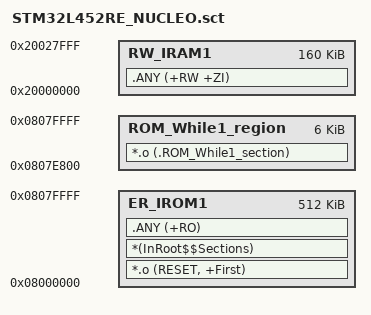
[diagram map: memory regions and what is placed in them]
; *************************************************************
; *** Scatter-Loading Description File generated by uVision ***
; *************************************************************

LR_IROM1 0x08000000 0x00080000  {    ; load region size_region
  ER_IROM1 0x08000000 0x00080000  {  ; load address = execution address
   *.o (RESET, +First)
   *(InRoot$$Sections)
   .ANY (+RO)
  }
  ROM_While1_region 0x0807E800 0x1800  {
   *.o (.ROM_While1_section)
  }
  RW_IRAM1 0x20000000 0x00028000  {  ; RW data
   .ANY (+RW +ZI)
  }
}

